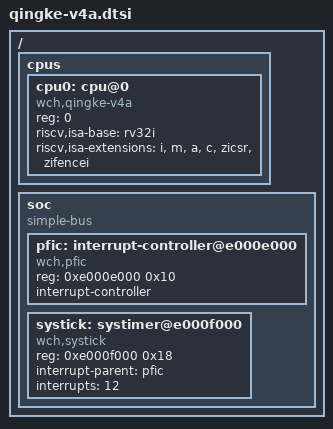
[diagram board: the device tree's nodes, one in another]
/*
 * SPDX-FileCopyrightText: Copyright The Zephyr Project Contributors
 * SPDX-License-Identifier: Apache-2.0
 */

/ {
	#address-cells = <1>;
	#size-cells = <1>;

	cpus {
		#address-cells = <1>;
		#size-cells = <0>;

		cpu0: cpu@0 {
			compatible = "wch,qingke-v4a", "riscv";
			reg = <0>;
			device_type = "cpu";
			riscv,isa-base = "rv32i";
			riscv,isa-extensions = "i", "m", "a", "c", "zicsr", "zifencei";
		};
	};

	soc {
		compatible = "simple-bus";
		ranges;
		#address-cells = <1>;
		#size-cells = <1>;

		pfic: interrupt-controller@e000e000 {
			compatible = "wch,pfic";
			reg = <0xe000e000 0x10>;
			#address-cells = <0>;
			#interrupt-cells = <1>;
			interrupt-controller;
			status = "okay";
		};

		systick: systimer@e000f000 {
			compatible = "wch,systick";
			reg = <0xe000f000 0x18>;
			interrupt-parent = <&pfic>;
			interrupts = <12>;
			status = "okay";
		};
	};
};
